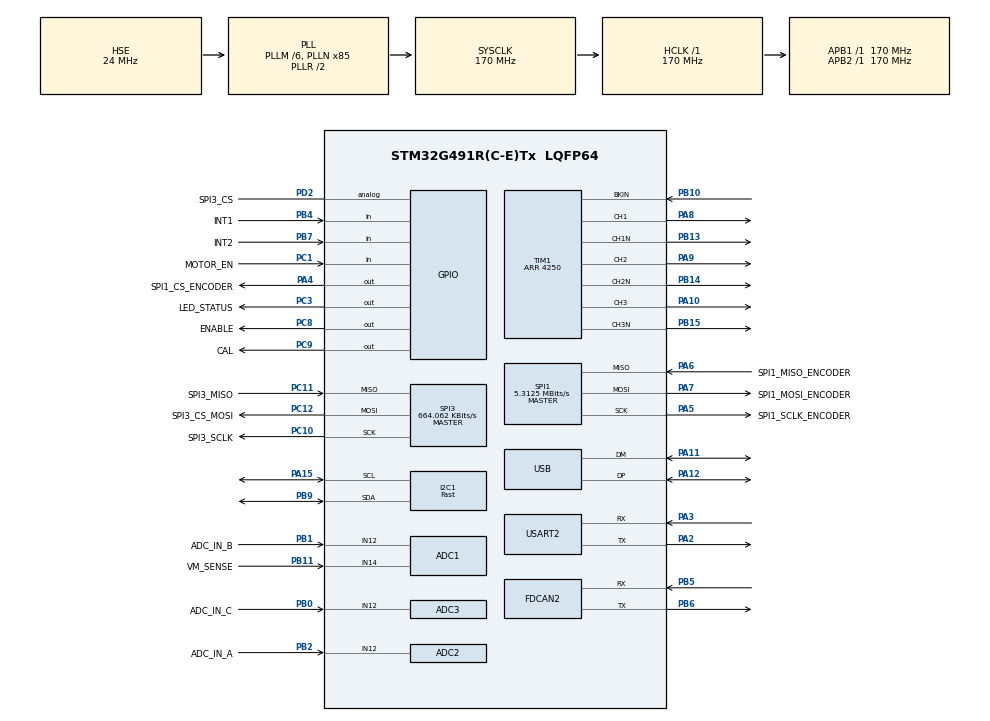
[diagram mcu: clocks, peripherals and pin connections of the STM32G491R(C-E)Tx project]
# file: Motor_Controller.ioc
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ADC1.Channel-1\#ChannelRegularConversion=ADC_CHANNEL_14
ADC1.EnableAnalogWatchDog1=false
ADC1.EnableInjectedConversion=ENABLE
ADC1.ExternalTrigInjecConv=ADC_EXTERNALTRIGINJEC_T1_TRGO2
ADC1.InjNumberOfConversion=1
ADC1.InjectedChannel-2\#ChannelInjectedConversion=ADC_CHANNEL_12
ADC1.InjectedOffsetNumber-2\#ChannelInjectedConversion=ADC_OFFSET_NONE
ADC1.InjectedRank-2\#ChannelInjectedConversion=1
ADC1.InjectedSamplingTime-2\#ChannelInjectedConversion=ADC_SAMPLETIME_2CYCLES_5
ADC1.NbrOfConversionFlag=1
ADC1.OffsetNumber-1\#ChannelRegularConversion=ADC_OFFSET_NONE
ADC1.Rank-1\#ChannelRegularConversion=1
ADC1.SamplingTime-1\#ChannelRegularConversion=ADC_SAMPLETIME_2CYCLES_5
ADC1.master=1
ADC2.EnableInjectedConversion=ENABLE
ADC2.EnableRegularConversion=DISABLE
ADC2.ExternalTrigInjecConv=ADC_EXTERNALTRIGINJEC_T1_TRGO2
ADC2.InjNumberOfConversion=1
ADC2.InjectedChannel-3\#ChannelInjectedConversion=ADC_CHANNEL_12
ADC2.InjectedOffsetNumber-3\#ChannelInjectedConversion=ADC_OFFSET_NONE
ADC2.InjectedRank-3\#ChannelInjectedConversion=1
ADC2.InjectedSamplingTime-3\#ChannelInjectedConversion=ADC_SAMPLETIME_2CYCLES_5
ADC2.Rank1_Channel=ADC_CHANNEL_12
ADC3.EnableInjectedConversion=ENABLE
ADC3.EnableRegularConversion=DISABLE
ADC3.ExternalTrigInjecConv=ADC_EXTERNALTRIGINJEC_T1_TRGO2
ADC3.InjNumberOfConversion=1
ADC3.InjectedChannel-3\#ChannelInjectedConversion=ADC_CHANNEL_12
ADC3.InjectedOffsetNumber-3\#ChannelInjectedConversion=ADC_OFFSET_NONE
ADC3.InjectedRank-3\#ChannelInjectedConversion=1
ADC3.InjectedSamplingTime-3\#ChannelInjectedConversion=ADC_SAMPLETIME_2CYCLES_5
ADC3.Rank1_Channel=ADC_CHANNEL_12
ADC3.master=1
FDCAN2.CalculateBaudRateNominal=500000
FDCAN2.CalculateTimeBitNominal=2000
FDCAN2.CalculateTimeQuantumNominal=100.0
FDCAN2.DataTimeSeg1=1
FDCAN2.DataTimeSeg2=1
FDCAN2.NominalPrescaler=17
FDCAN2.NominalTimeSeg1=15
FDCAN2.NominalTimeSeg2=4
I2C1.I2C_Speed_Mode=I2C_Fast
I2C1.Timing=0x40621236
Mcu.Family=STM32G4
Mcu.Name=STM32G491R(C-E)Tx
Mcu.Package=LQFP64
NVIC.ADC1_2_IRQn=true\:0\:0\:false\:false\:false\:true\:true\:true
NVIC.FDCAN2_IT0_IRQn=true\:6\:0\:true\:false\:true\:true\:true\:true
NVIC.FDCAN2_IT1_IRQn=true\:6\:0\:true\:false\:true\:true\:true\:true
NVIC.PriorityGroup=NVIC_PRIORITYGROUP_4
NVIC.TIM1_BRK_TIM15_IRQn=true\:0\:0\:false\:false\:true\:true\:true\:true
NVIC.USART2_IRQn=true\:6\:0\:true\:false\:true\:true\:true\:true
NVIC.USB_LP_IRQn=true\:6\:0\:true\:false\:true\:false\:true\:true
PA10.Signal=S_TIM1_CH3
PA11.Mode=Device
PA11.Signal=USB_DM
PA12.Mode=Device
PA12.Signal=USB_DP
PA13.Mode=Trace_Asynchronous_SW
PA13.Signal=SYS_JTMS-SWDIO
PA14.Mode=Trace_Asynchronous_SW
PA14.Signal=SYS_JTCK-SWCLK
PA15.Mode=I2C
PA15.Signal=I2C1_SCL
PA2.Mode=Asynchronous
PA2.Signal=USART2_TX
PA3.Mode=Asynchronous
PA3.Signal=USART2_RX
PA4.GPIO_Label=SPI1_CS_ENCODER
PA4.PinState=GPIO_PIN_SET
PA4.Signal=GPIO_Output
PA5.GPIO_Label=SPI1_SCLK_ENCODER
PA5.Mode=Full_Duplex_Master
PA5.Signal=SPI1_SCK
PA6.GPIO_Label=SPI1_MISO_ENCODER
PA6.Mode=Full_Duplex_Master
PA6.Signal=SPI1_MISO
PA7.GPIO_Label=SPI1_MOSI_ENCODER
PA7.Mode=Full_Duplex_Master
PA7.Signal=SPI1_MOSI
PA8.Signal=S_TIM1_CH1
PA9.Signal=S_TIM1_CH2
PB0.GPIO_Label=ADC_IN_C
PB0.Mode=IN12-Single-Ended
PB0.Signal=ADC3_IN12
PB1.GPIO_Label=ADC_IN_B
PB1.Mode=IN12-Single-Ended
PB1.Signal=ADC1_IN12
PB10.Mode=Activate-Break-Input
PB10.Signal=TIM1_BKIN
PB11.GPIO_Label=VM_SENSE
PB11.Mode=IN14-Single-Ended
PB11.Signal=ADC1_IN14
PB13.Mode=PWM Generation1 CH1 CH1N
PB13.Signal=TIM1_CH1N
PB14.Mode=PWM Generation2 CH2 CH2N
PB14.Signal=TIM1_CH2N
PB15.Mode=PWM Generation3 CH3 CH3N
PB15.Signal=TIM1_CH3N
PB2.GPIO_Label=ADC_IN_A
PB2.Mode=IN12-Single-Ended
PB2.Signal=ADC2_IN12
PB3.Mode=Trace_Asynchronous_SW
PB3.Signal=SYS_JTDO-SWO
PB4.GPIO_Label=INT1
PB4.Signal=GPIO_Input
PB5.Mode=FDCAN_Activate
PB5.Signal=FDCAN2_RX
PB6.Mode=FDCAN_Activate
PB6.Signal=FDCAN2_TX
PB7.GPIO_Label=INT2
PB7.Signal=GPIO_Input
PB9.Mode=I2C
PB9.Signal=I2C1_SDA
PC1.GPIO_Label=MOTOR_EN
PC1.Signal=GPIO_Input
PC10.GPIO_Label=SPI3_SCLK
PC10.Mode=Full_Duplex_Master
PC10.Signal=SPI3_SCK
PC11.GPIO_Label=SPI3_MISO
PC11.Mode=Full_Duplex_Master
PC11.Signal=SPI3_MISO
PC12.GPIO_Label=SPI3_CS_MOSI
PC12.Mode=Full_Duplex_Master
PC12.Signal=SPI3_MOSI
PC3.GPIO_Label=LED_STATUS
PC3.Signal=GPIO_Output
PC8.GPIO_Label=ENABLE
PC8.Signal=GPIO_Output
PC9.GPIO_Label=CAL
PC9.Signal=GPIO_Output
PD2.GPIO_Label=SPI3_CS
PD2.Signal=GPIO_Analog
PF0-OSC_IN.Mode=HSE-External-Oscillator
PF0-OSC_IN.Signal=RCC_OSC_IN
PF1-OSC_OUT.Mode=HSE-External-Oscillator
PF1-OSC_OUT.Signal=RCC_OSC_OUT
ProjectManager.HeapSize=0x200
ProjectManager.StackSize=0x400
ProjectManager.TargetToolchain=CMake
RCC.ADC12Freq_Value=170000000
RCC.ADC345Freq_Value=170000000
RCC.AHBFreq_Value=170000000
RCC.APB1Freq_Value=170000000
RCC.APB1TimFreq_Value=170000000
RCC.APB2Freq_Value=170000000
RCC.APB2TimFreq_Value=170000000
RCC.CortexFreq_Value=170000000
RCC.EXTERNAL_CLOCK_VALUE=12288000
RCC.HCLKFreq_Value=170000000
RCC.HSE_VALUE=24000000
RCC.HSI48_VALUE=48000000
RCC.HSI_VALUE=16000000
RCC.LSE_VALUE=32768
RCC.PLLM=RCC_PLLM_DIV6
RCC.PLLN=85
RCC.PLLSourceVirtual=RCC_PLLSOURCE_HSE
RCC.SYSCLKFreq_VALUE=170000000
RCC.SYSCLKSource=RCC_SYSCLKSOURCE_PLLCLK
RCC.VCOOutputFreq_Value=340000000
SH.S_TIM1_CH1.0=TIM1_CH1,PWM Generation1 CH1 CH1N
SH.S_TIM1_CH2.0=TIM1_CH2,PWM Generation2 CH2 CH2N
SH.S_TIM1_CH3.0=TIM1_CH3,PWM Generation3 CH3 CH3N
SPI1.BaudRatePrescaler=SPI_BAUDRATEPRESCALER_32
SPI1.CLKPhase=SPI_PHASE_2EDGE
SPI1.CalculateBaudRate=5.3125 MBits/s
SPI1.DataSize=SPI_DATASIZE_12BIT
SPI1.Direction=SPI_DIRECTION_2LINES
SPI1.Mode=SPI_MODE_MASTER
SPI1.VirtualType=VM_MASTER
SPI3.BaudRatePrescaler=SPI_BAUDRATEPRESCALER_256
SPI3.CLKPhase=SPI_PHASE_2EDGE
SPI3.CalculateBaudRate=664.062 KBits/s
SPI3.DataSize=SPI_DATASIZE_16BIT
SPI3.Direction=SPI_DIRECTION_2LINES
SPI3.Mode=SPI_MODE_MASTER
SPI3.VirtualType=VM_MASTER
TIM1.BreakPolarity=TIM_BREAKPOLARITY_LOW
TIM1.Channel-PWM\ Generation1\ CH1\ CH1N=TIM_CHANNEL_1
TIM1.Channel-PWM\ Generation2\ CH2\ CH2N=TIM_CHANNEL_2
TIM1.Channel-PWM\ Generation3\ CH3\ CH3N=TIM_CHANNEL_3
TIM1.Channel-PWM\ Generation4\ No\ Output=TIM_CHANNEL_4
TIM1.CounterMode=TIM_COUNTERMODE_CENTERALIGNED1
TIM1.DeadTime=17
TIM1.OffStateIDLEMode=TIM_OSSI_ENABLE
TIM1.OffStateRunMode=TIM_OSSR_ENABLE
TIM1.PeriodNoDither=4250
TIM1.PulseNoDither_4=4200
TIM1.TIM_MasterOutputTrigger2=TIM_TRGO2_OC4REF
USART2.VirtualMode-Asynchronous=VM_ASYNC
USB_DEVICE.CLASS_NAME_FS=CDC
USB_DEVICE.VirtualMode=Cdc
USB_DEVICE.VirtualModeFS=Cdc_FS
VP_CORDIC_VS_CORDIC.Mode=CORDIC_Activate
VP_DAC3_VS_DACI1.Mode=DAC_OUT1_Int
VP_RCC_VS_USB.Mode=USB_FS
VP_SYS_VS_DBSignals.Mode=DisableDeadBatterySignals
VP_TIM1_VS_ClockSourceINT.Mode=Internal
VP_TIM1_VS_no_output4.Mode=PWM Generation4 No Output
VP_USB_DEVICE_VS_USB_DEVICE_CDC_FS.Mode=CDC_FS
board=custom

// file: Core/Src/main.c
/* USER CODE BEGIN Header */
/**
  ******************************************************************************
  * @file           : main.c
  * @brief          : Main program body
  ******************************************************************************
  * @attention
  *
  * Copyright (c) 2026 STMicroelectronics.
  * All rights reserved.
  *
  * This software is licensed under terms that can be found in the LICENSE file
  * in the root directory of this software component.
  * If no LICENSE file comes with this software, it is provided AS-IS.
  *
  ******************************************************************************
  */
/* USER CODE END Header */
#include "main.h"
#include "adc.h"
#include "cordic.h"
#include "dac.h"
#include "fdcan.h"
#include "i2c.h"
#include "spi.h"
#include "tim.h"
#include "usart.h"
#include "usb_device.h"
#include "gpio.h"

/* USER CODE BEGIN Includes */
#include "app.h"
/* USER CODE END Includes */

void SystemClock_Config(void);

int main(void)
{

  /* MCU Configuration--------------------------------------------------------*/

  /* Reset of all peripherals, Initializes the Flash interface and the Systick. */
  HAL_Init();

  /* Configure the system clock */
  SystemClock_Config();

  /* USER CODE BEGIN SysInit */
  app_clock_init();

  /* USER CODE END SysInit */

  /* Initialize all configured peripherals */
  MX_GPIO_Init();
  MX_ADC1_Init();
  MX_ADC2_Init();
  MX_ADC3_Init();
  MX_SPI1_Init();
  MX_SPI3_Init();
  MX_TIM1_Init();
  MX_DAC3_Init();
  MX_CORDIC_Init();
  MX_FDCAN2_Init();
  MX_I2C1_Init();
  MX_USART2_UART_Init();
  MX_USB_Device_Init();
  /* USER CODE BEGIN 2 */
  app_init();
  /* USER CODE END 2 */

  /* Infinite loop */
  while (1)
  {

    /* USER CODE BEGIN 3 */
    app_loop();
  }
  /* USER CODE END 3 */
}

void SystemClock_Config(void)
{
  RCC_OscInitTypeDef RCC_OscInitStruct = {0};
  RCC_ClkInitTypeDef RCC_ClkInitStruct = {0};
  RCC_CRSInitTypeDef pInit = {0};

  /** Configure the main internal regulator output voltage
  */
  HAL_PWREx_ControlVoltageScaling(PWR_REGULATOR_VOLTAGE_SCALE1_BOOST);

  /** Initializes the RCC Oscillators according to the specified parameters
  * in the RCC_OscInitTypeDef structure.
  */
  RCC_OscInitStruct.OscillatorType = RCC_OSCILLATORTYPE_HSI48|RCC_OSCILLATORTYPE_HSE;
  RCC_OscInitStruct.HSEState = RCC_HSE_ON;
  RCC_OscInitStruct.HSI48State = RCC_HSI48_ON;
  RCC_OscInitStruct.PLL.PLLState = RCC_PLL_ON;
  RCC_OscInitStruct.PLL.PLLSource = RCC_PLLSOURCE_HSE;
  RCC_OscInitStruct.PLL.PLLM = RCC_PLLM_DIV6;
  RCC_OscInitStruct.PLL.PLLN = 85;
  RCC_OscInitStruct.PLL.PLLP = RCC_PLLP_DIV2;
  RCC_OscInitStruct.PLL.PLLQ = RCC_PLLQ_DIV2;
  RCC_OscInitStruct.PLL.PLLR = RCC_PLLR_DIV2;
  if (HAL_RCC_OscConfig(&RCC_OscInitStruct) != HAL_OK)
  {
    Error_Handler();
  }

  /** Initializes the CPU, AHB and APB buses clocks
  */
  RCC_ClkInitStruct.ClockType = RCC_CLOCKTYPE_HCLK|RCC_CLOCKTYPE_SYSCLK
                              |RCC_CLOCKTYPE_PCLK1|RCC_CLOCKTYPE_PCLK2;
  RCC_ClkInitStruct.SYSCLKSource = RCC_SYSCLKSOURCE_PLLCLK;
  RCC_ClkInitStruct.AHBCLKDivider = RCC_SYSCLK_DIV1;
  RCC_ClkInitStruct.APB1CLKDivider = RCC_HCLK_DIV1;
  RCC_ClkInitStruct.APB2CLKDivider = RCC_HCLK_DIV1;

  if (HAL_RCC_ClockConfig(&RCC_ClkInitStruct, FLASH_LATENCY_4) != HAL_OK)
  {
    Error_Handler();
  }

  /** Enable the SYSCFG APB clock
  */
  __HAL_RCC_CRS_CLK_ENABLE();

  /** Configures CRS
  */
  pInit.Prescaler = RCC_CRS_SYNC_DIV1;
  pInit.Source = RCC_CRS_SYNC_SOURCE_USB;
  pInit.Polarity = RCC_CRS_SYNC_POLARITY_RISING;
  pInit.ReloadValue = __HAL_RCC_CRS_RELOADVALUE_CALCULATE(48000000,1000);
  pInit.ErrorLimitValue = 34;
  pInit.HSI48CalibrationValue = 32;

  HAL_RCCEx_CRSConfig(&pInit);
}

void Error_Handler(void)
{
  __disable_irq();
  while (1)
  {
  }
}
